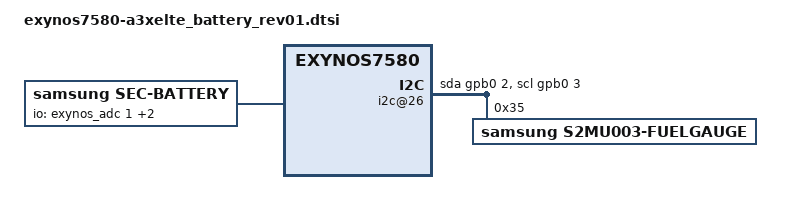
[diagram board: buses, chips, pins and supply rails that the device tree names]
/*
 * SAMSUNG UNIVERSAL7580 board device tree source
 *
 * Copyright (c) 2013 Samsung Electronics Co., Ltd.
 *		http://www.samsung.com
 *
 * This program is free software; you can redistribute it and/or modify
 * it under the terms of the GNU General Public License version 2 as
 * published by the Free Software Foundation.
*/

/ {
	pinctrl@139B0000 {
		fuel_irq: fuel-irq {
		samsung,pins = "gpa0-1";
		samsung,pin-function = <0>;
		samsung,pin-pud = <0>;
		samsung,pin-drv = <0>;
		};
	};

	battery {
		status = "okay";
		compatible = "samsung,sec-battery";
		battery,vendor = "SDI SDI";
		battery,charger_name = "sec-charger";
		battery,fuelgauge_name = "sec-fuelgauge";
		battery,technology = <2>; /* POWER_SUPPLY_TECHNOLOGY_LION */
		/* .temp_cohot = -1000; */
		/* .temp_cocold = -4325; */

		battery,chip_vendor = "LSI";
		battery,temp_adc_type = <1>; /* SEC_BATTERY_ADC_TYPE_AP */

		battery,polling_time = <10 30 30 30 3600>;
		battery,chg_temp_check = <0>;

		battery,temp_table_adc = <664 690 767 816 897 1035 1194 1253 1359 1547 1747 1961 2179
								2398 2609 2798 2977 3089 3153 3277 3391 3487>;

		battery,temp_table_data = <650 630 600 580 550 500 450 430 400 350 300 250 200
								150 100 50 0 (-30) (-50) (-100) (-150) (-200)>;

		battery,chg_temp_table_adc = <215 224 234 243 253 262 271 281 290 300
					   309 322 335 348 361 374 389 404 418 433
					   448 465 482 499 516 533 553 573 594 614
					   634 658 682 705 729 753 780 807 833 860
					   887 918 948 979 1009 1040 1076 1112 1147 1183
					   1219 1257 1295 1332 1370 1408 1448 1489 1529 1570
					   1610 1653 1696 1739 1782 1825 1869 1913 1957 2001
					   2045 2090 2134 2179 2223 2268 2310 2352 2395 2437
					   2479 2520 2561 2601 2642 2683 2720 2757 2793 2830
					   2867 2903 2939 2975 3011 3047 3077 3106 3136 3165
					   3195 3221 3247 3274 3300 3326 3348 3370 3392 3414 3436>;
		battery,chg_temp_table_data = <900 890 880 870 860 850 840 830 820 810
					   800 790 780 770 760 750 740 730 720 710
					   700 690 680 670 660 650 640 630 620 610
					   600 590 580 570 560 550 540 530 520 510
					   500 490 480 470 460 450 440 430 420 410
					   400 390 380 370 360 350 340 330 320 310
					   300 290 280 270 260 250 240 230 220 210
					   200 190 180 170 160 150 140 130 120 110
					   100 90 80 70 60 50 40 30 20 10
					   0 (-10) (-20) (-30) (-40) (-50) (-60) (-70) (-80) (-90)
					   (-100) (-110) (-120) (-130) (-140) (-150) (-160) (-170) (-180) (-190) (-200)>;

		battery,input_current_limit = <1500 0 0 1500 460 900 1000 460 1000 0 820 1500 1500 0 0 400 700 1300 300 1000 1500 0 1500 1000 1500 80 1500 1500 1400 1000 1000>;
		battery,fast_charging_current = <1700 0 0 1700 460 1200 1000 460 1200 0 1200 1600 1700 0 0 400 700 1300 300 1000 1500 0 1700 1000 1700 80 1700 1000 1400 0 1000>;
		battery,full_check_current_1st = <200 0 0 200 200 200 200 200 200 0 200 200 200 0 0 200 200 200 200 200 200 0 200 200 200 0 200 200 200 0 200>;
		battery,full_check_current_2nd = <125 0 0 125 125 125 125 125 125 0 125 125 125 0 0 125 125 125 125 125 125 0 125 125 125 0 125 125 125 0 125>;

		battery,adc_check_count = <5>;

		battery,inbat_voltage = <1>;
		battery,inbat_voltage_table_adc = <3143 3118 3083 3048 3012 2973 2947 2910 2873 2838 2802 2765 2732 2697 2662 2627 2595 2560 2522 2487 2453>;
		battery,inbat_voltage_table_data = <4380 4350 4300 4260 4190 4160 4100 4050 4000 3950 3900 3850 3800 3750 3700 3650 3600 3550 3500 3450 3400>;

		battery,cable_check_type = <4>; /* SEC_BATTERY_CABLE_CHECK_PSY */
		battery,cable_source_type = <1>; /* SEC_BATTERY_CABLE_SOURCE_EXTERNAL */
		battery,event_waiting_time = <600>;
		battery,polling_type = <1>; /* SEC_BATTERY_MONITOR_ALARM */
		battery,monitor_initial_count = <0>;

		battery,battery_check_type = <0>; /* SEC_BATTERY_CHECK_NONE */
		battery,check_count = <0>;
		battery,check_adc_max = <1440>;
		battery,check_adc_min = <0>;

		battery,ovp_uvlo_check_type = <3>; /* SEC_BATTERY_OVP_UVLO_CHGPOLLING */

		battery,thermal_source = <2>; /* SEC_BATTERY_THERMAL_SOURCE_ADC */

		battery,temp_check_type = <2>; /* _BATTERY_TEMP_CHECK_TEMP */
		battery,temp_check_count = <1>;
		battery,temp_highlimit_threshold_event = <800>;
		battery,temp_highlimit_recovery_event = <750>;
		battery,temp_high_threshold_event = <550>;
		battery,temp_high_recovery_event = <500>;
		battery,temp_low_threshold_event = <(-50)>;
		battery,temp_low_recovery_event = <0>;
		battery,temp_highlimit_threshold_normal = <800>;
		battery,temp_highlimit_recovery_normal = <750>;
		battery,temp_high_threshold_normal = <550>;
		battery,temp_high_recovery_normal = <500>;
		battery,temp_low_threshold_normal = <(-50)>;
		battery,temp_low_recovery_normal = <0>;
		battery,temp_highlimit_threshold_lpm = <800>;
		battery,temp_highlimit_recovery_lpm = <750>;
		battery,temp_high_threshold_lpm = <550>;
		battery,temp_high_recovery_lpm = <500>;
		battery,temp_low_threshold_lpm = <(-50)>;
		battery,temp_low_recovery_lpm = <0>;
		battery,full_check_type = <7>; /* SEC_BATTERY_FULLCHARGED_CHGPSY */
		battery,full_check_type_2nd = <7>; /* SEC_BATTERY_FULLCHARGED_CHGPSY */
		battery,full_check_count = <1>;
		battery,chg_gpio_full_check = <0>;
		battery,chg_polarity_full_check = <1>;

		battery,chg_high_temp_1st = <530>;
		battery,chg_high_temp_2nd = <530>;
		battery,chg_high_temp_recovery = <525>;
		battery,chg_charging_limit_current = <1300>;
		battery,chg_charging_limit_current_2nd = <1300>;
		battery,chg_skip_check_capacity = <10>;
		battery,chg_skip_check_time = <600>;

		/* SEC_BATTERY_FULL_CONDITION_SOC |
		   SEC_BATTERY_FULL_CONDITION_NOTIMEFULL |
		   SEC_BATTERY_FULL_CONDITION_VCELL */
		battery,full_condition_type = <13>;
		battery,full_condition_soc = <93>;
		battery,full_condition_vcell = <4250>;

		battery,recharge_check_count = <2>;
		battery,recharge_condition_type = <4>; /* SEC_BATTERY_RECHARGE_CONDITION_VCELL */
		battery,recharge_condition_soc = <98>;
		battery,recharge_condition_vcell = <4280>;

		battery,standard_curr = <1700>;
		battery,expired_time = <12240>; /* 204 min*/
		battery,recharging_expired_time = <5400>;
		battery,charging_reset_time = <0>;

		battery,chg_float_voltage = <4350>;

		battery,self_discharging_temp_block = <600>;
		battery,self_discharging_volt_block = <4250>;
		battery,self_discharging_temp_recov = <550>;
		battery,self_discharging_temp_pollingtime = <400>;

		battery,swelling_low_temp_2step_mode = <1>;
		battery,swelling_high_temp_block = <410>;
		battery,swelling_high_temp_recov = <390>;
		battery,swelling_low_temp_block_1st = <150>;
		battery,swelling_low_temp_recov_1st = <200>;
		battery,swelling_low_temp_block_2nd = <50>;
		battery,swelling_low_temp_recov_2nd = <100>;

		battery,swelling_low_temp_current = <700>;		/* 0.3C */
		battery,swelling_low_temp_topoff = <125>;		/* 0.05C */
		battery,swelling_high_temp_current = <1000>;	/* 0.45C */
		battery,swelling_high_temp_topoff = <125>;		/* 0.05C */

		battery,swelling_drop_float_voltage = <4150>;
		battery,swelling_high_rechg_voltage = <4000>;
		battery,swelling_low_rechg_voltage = <4000>;
		battery,swelling_block_time = <600>;

		/* cycle, chg_float_voltage, recharge_condition_vcell, full_condition_vcell, full_condition_soc */
		battery,age_data = <0 4350 4280 4250 93
				200  4330 4260 4230 92
				250  4310 4240 4210 91
				300  4290 4220 4190 90
				1000 4240 4170 4140 89>;

		io-channels = <&exynos_adc 1>, <&exynos_adc 3>, <&exynos_adc 4>;
		io-channel-names = "adc-temp", "chg-adc-temp", "in-bat-adc";
		#io-channel-cells = <3>;
		io-channel-ranges;
	};

	i2c@26 {
		compatible = "i2c-gpio";
		gpios = <&gpb0 2 0
			&gpb0 3 0>;
		i2c-gpio,delay-us = <5>;
		#address-cells = <1>;
		#size-cells = <0>;
		status = "okay";
		s2mu003-fuelgauge@35 {
			compatible = "samsung,s2mu003-fuelgauge";
			reg = <0x35>;
			pinctrl-names = "default";
			pinctrl-0 = <&fuel_irq>;
			fuelgauge,fuel_alert = <&gpa0 1 0>;
			fuelgauge,fuel_alert_soc = <1>;
			fuelgauge,capacity_max = <990>;
			fuelgauge,capacity_max_margin = <70>;
			fuelgauge,capacity_min = <0>;
			fuelgauge,capacity_calculation_type = <28>;
			fuelgauge,repeated_fuelalert;
			fuelgauge,type_str = "SDI";
		};
	};

	s2mu003-charger {
		status = "disable";
		compatible = "samsung,s2mu003-charger";
		battery,is_1MHz_switching = <1>;
		battery,chg_gpio_en = <0>;
		battery,chg_polarity_en = <0>;
		battery,chg_gpio_status = <0>;
		battery,chg_polarity_status = <0>;
		battery,chg_float_voltage = <4350>;
	};
};
